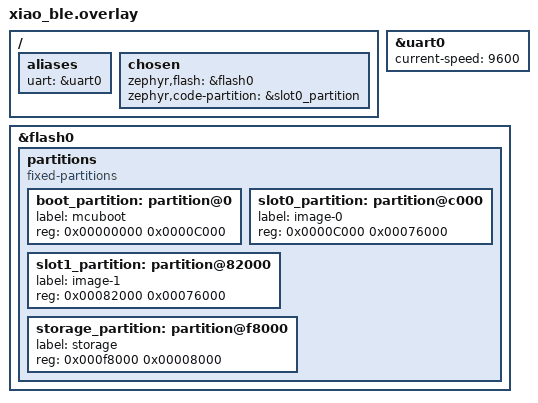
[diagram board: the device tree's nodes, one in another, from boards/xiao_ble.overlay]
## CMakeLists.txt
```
cmake_minimum_required(VERSION 3.20.0)

# Specify the C standard
set(CMAKE_C_STANDARD 17)
set(CMAKE_EXPORT_COMPILE_COMMANDS ON)

add_compile_definitions(ZB_ZCL_SUPPORT_CLUSTER_ELECTRICAL_MEASUREMENT=1)

find_package(Zephyr REQUIRED HINTS $ENV{ZEPHYR_BASE})
project("Smart Meter Zigbee")

FILE(GLOB app_sources src/*.c)
FILE(GLOB libsml_sources libsml/sml/src/*.c)
list(REMOVE_ITEM libsml_sources "${CMAKE_CURRENT_SOURCE_DIR}/libsml/sml/src/sml_transport.c")

target_compile_options(app PRIVATE -Wall -Wextra)
target_sources(app PRIVATE ${app_sources} ${libsml_sources})
target_include_directories(app PRIVATE ${CMAKE_CURRENT_SOURCE_DIR}/inc ${CMAKE_CURRENT_SOURCE_DIR}/libsml/sml/include)
target_compile_definitions(app PRIVATE SML_NO_UUID_LIB=1)
```

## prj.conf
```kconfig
# LOG configuration
CONFIG_LOG=n
CONFIG_LOG_CMDS=n

CONFIG_GPIO=n

# bootloader config
CONFIG_BUILD_OUTPUT_UF2=n
CONFIG_BOOTLOADER_MCUBOOT=y


# Shell
CONFIG_SHELL=n
# CONFIG_SHELL_BACKEND_SERIAL_RX_RING_BUFFER_SIZE=128


# Zigbee
CONFIG_ZIGBEE=y
CONFIG_ZIGBEE_APP_UTILS=y
CONFIG_ZIGBEE_ROLE_ROUTER=y
CONFIG_ZIGBEE_CHANNEL=11

CONFIG_BOOT_DELAY=0

# Enable nRF ECB driver
CONFIG_CRYPTO=y
CONFIG_CRYPTO_NRF_ECB=y
CONFIG_CRYPTO_INIT_PRIORITY=80

# This example requires more workqueue stack
CONFIG_SYSTEM_WORKQUEUE_STACK_SIZE=2048
CONFIG_MAIN_THREAD_PRIORITY=7

# LIBC config
#CONFIG_MINIMAL_LIBC_MALLOC_ARENA_SIZE=32768
CONFIG_NEWLIB_LIBC=y

# Networking
CONFIG_NET_IPV6=n
CONFIG_NET_IP_ADDR_CHECK=n
CONFIG_NET_UDP=n

#######################
# Zigbee FOTA overlay #
#######################

# Enable Zigbee FOTA library
CONFIG_ZIGBEE_FOTA=y
CONFIG_ZIGBEE_FOTA_HW_VERSION=52
CONFIG_ZIGBEE_FOTA_ENDPOINT=5
CONFIG_MCUBOOT_IMAGE_VERSION="0.1.0"
CONFIG_ZIGBEE_FOTA_COMMENT="SMZ"

# Ensure an MCUboot-compatible binary is generated.
CONFIG_IMG_MANAGER=y
CONFIG_DFU_TARGET_MCUBOOT=y
CONFIG_IMG_ERASE_PROGRESSIVELY=y
CONFIG_ZIGBEE_FOTA_PROGRESS_EVT=y

# Increase the number of RX buffers
CONFIG_NRF_802154_RX_BUFFERS=32
```

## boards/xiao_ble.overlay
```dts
/ {
     aliases {
             uart = &uart0;
     };
    chosen {
        zephyr,flash = &flash0;
        zephyr,code-partition = &slot0_partition;
    };
};

&uart0 {
    current-speed = <9600>;
};


/* Delete the existing partitions */
/delete-node/ &sd_partition;
/delete-node/ &code_partition;
/delete-node/ &storage_partition;
/delete-node/ &boot_partition;
&flash0 {
    partitions {
        compatible = "fixed-partitions";
        #address-cells = <1>;
        #size-cells = <1>;

        boot_partition: partition@0 {
            label = "mcuboot";
            reg = <0x00000000 0x0000C000>;
        };
        slot0_partition: partition@c000 {
            label = "image-0";
            reg = <0x0000C000 0x00076000>;
        };
        slot1_partition: partition@82000 {
            label = "image-1";
            reg = <0x00082000 0x00076000>;
        };
        /*
         * The flash starting at 0x000f8000 and ending at
         * 0x000fffff is reserved for use by the application.
         *
         * Storage partition will be used by FCB/LittleFS/NVS
         * if enabled.
         */
        storage_partition: partition@f8000 {
            label = "storage";
            reg = <0x000f8000 0x00008000>;
        };
    };
};
```

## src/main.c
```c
/* Includes ------------------------------------------------------------------*/
#include "sml_processing.h"
#include "zigbee.h"
/* LOG channel def -----------------------------------------------------------*/
/* Private typedef -----------------------------------------------------------*/
/* Private define ------------------------------------------------------------*/
/* Private macro -------------------------------------------------------------*/
/* Private variables ---------------------------------------------------------*/
/* Private function prototypes -----------------------------------------------*/
/* Private functions ---------------------------------------------------------*/
void main(void) {
    if (init_sml_processing() != 0) {
        return;
    }
    // The Zigbee thread will wait until the first sml message
    start_zigbee();
    start_sml_processing();
}
/* Exported functions --------------------------------------------------------*/
```

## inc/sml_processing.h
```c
/* Define to prevent recursive inclusion -------------------------------------*/
#ifndef SML_PROCESSING_H
#define SML_PROCESSING_H
/* Includes ------------------------------------------------------------------*/
/* Exported types ------------------------------------------------------------*/
/* Exported constants --------------------------------------------------------*/
/* Exported macro ------------------------------------------------------------*/
/* Exported variables --------------------------------------------------------*/
/* Exported functions --------------------------------------------------------*/
/* Initialization and Configuration functions  ******************************/
int init_sml_processing(void);
void start_sml_processing(void);
/* Private types -------------------------------------------------------------*/
/* Private variables ---------------------------------------------------------*/
/* Private constants ---------------------------------------------------------*/
#define SML_RX_BUFFER_SIZE 1024
/* Private macros ------------------------------------------------------------*/
/* Private functions ---------------------------------------------------------*/

#endif  // SML_PROCESSING_H
```

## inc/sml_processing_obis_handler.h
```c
/* Define to prevent recursive inclusion -------------------------------------*/
#ifndef SML_PROCESSING_OBIS_HANDLER_H
#define SML_PROCESSING_OBIS_HANDLER_H
/* Includes ------------------------------------------------------------------*/
#include <zephyr/sys/atomic.h>

#include "sml/sml_list.h"
/* Exported types ------------------------------------------------------------*/
/* Exported constants --------------------------------------------------------*/
typedef enum {
    ACTIVE_ENERGY_IMPORT_FLAG = 1 << 0,
    ACTIVE_ENERGY_EXPORT_FLAG = 1 << 1,
    CURRENT_ACTIVE_POWER_FLAG = 1 << 2,
    VOLTAGE_L1_FLAG = 1 << 3,
    VOLTAGE_L2_FLAG = 1 << 4,
    VOLTAGE_L3_FLAG = 1 << 5,
    CURRENT_L1_FLAG = 1 << 6,
    CURRENT_L2_FLAG = 1 << 7,
    CURRENT_L3_FLAG = 1 << 8,
    ANGLE_L1_FLAG = 1 << 9,
    ANGLE_L2_FLAG = 1 << 10,
    ANGLE_L3_FLAG = 1 << 11,
    FREQUENCY_FLAG = 1 << 12,
} sml_obis_flag_t;
/* Exported macro ------------------------------------------------------------*/
/* Exported variables --------------------------------------------------------*/
extern atomic_t sml_obis_initialized;
/* Exported functions --------------------------------------------------------*/
void process_active_energy_import(sml_list *entry);
void process_current_active_power(sml_list *entry);
void process_voltage_l1(sml_list *entry);
void process_voltage_l2(sml_list *entry);
void process_voltage_l3(sml_list *entry);
void process_current_l1(sml_list *entry);
void process_current_l2(sml_list *entry);
void process_current_l3(sml_list *entry);
void process_frequency(sml_list *entry);
void process_default_handler(sml_list *entry);
void ignore_obis_value(sml_list *entry);
/* Private types -------------------------------------------------------------*/
/* Private variables ---------------------------------------------------------*/

/* Private constants ---------------------------------------------------------*/
/* Private macros ------------------------------------------------------------*/
/* Private functions ---------------------------------------------------------*/




#endif  // SML_PROCESSING_OBIS_HANDLER_H
```

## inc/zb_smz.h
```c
/* Define to prevent recursive inclusion -------------------------------------*/
#ifndef ZB_SMZ_H
#define ZB_SMZ_H
/* Includes ------------------------------------------------------------------*/
#include <zboss_api.h>
/* Exported types ------------------------------------------------------------*/
typedef struct {
    zb_uint32_t measurement_type;
    zb_uint16_t rmsCurrentPhA;
    zb_uint16_t rmsCurrentPhB;
    zb_uint16_t rmsCurrentPhC;
    zb_uint16_t rmsVoltagePhA;
    zb_uint16_t rmsVoltagePhB;
    zb_uint16_t rmsVoltagePhC;
    zb_uint16_t acFrequency;
    zb_uint16_t voltageMultiplier;
    zb_uint16_t voltageDivisor;
    zb_uint16_t currentMultiplier;
    zb_uint16_t currentDivisor;
    zb_uint16_t powerMultiplier;
    zb_uint16_t powerDivisor;
    zb_uint16_t frequencyMultiplier;
    zb_uint16_t frequencyDivisor;
    zb_uint16_t powerFactor;
} zb_zcl_el_measurement_attrs_ext_t;

typedef struct {
    zb_uint48_t curr_summ_delivered;
    zb_int24_t instantaneous_demand;
    zb_uint24_t multiplier;
    zb_uint24_t divisor;
} zb_zcl_metering_attrs_custom_t;
/* Exported constants --------------------------------------------------------*/
/** SMZ Device ID*/
#define ZB_SMZ_DEVICE_ID 0x0008
/** SMZ device version */
#define ZB_DEVICE_VER_SMZ 0
/** SMZ IN (server) clusters number */
#define ZB_SMZ_IN_CLUSTER_NUM 4
/** SMZ OUT (client) clusters number */
#define ZB_SMZ_OUT_CLUSTER_NUM 0
#define ZB_SMZ_CLUSTER_NUM (ZB_SMZ_IN_CLUSTER_NUM + ZB_SMZ_OUT_CLUSTER_NUM)
#define ZB_SMZ_EL_REPORT_COUNT 7
#define ZB_SMZ_METERING_REPORT_COUNT 2
/** Number of attribute for reporting on SMZ device */
#define ZB_SMZ_REPORT_ATTR_COUNT ZB_SMZ_EL_REPORT_COUNT + ZB_SMZ_METERING_REPORT_COUNT
/* Exported macro ------------------------------------------------------------*/
#define ZB_SET_ATTR_DESCR_WITH_ZB_ZCL_ATTR_ELECTRICAL_MEASUREMENT_ACTIVE_POWER_PHB_ID(data_ptr) \
    {                                                                                           \
        ZB_ZCL_ATTR_ELECTRICAL_MEASUREMENT_ACTIVE_POWER_PHB_ID, ZB_ZCL_ATTR_TYPE_S16,           \
            ZB_ZCL_ATTR_ACCESS_READ_ONLY | ZB_ZCL_ATTR_ACCESS_REPORTING, (void *)data_ptr       \
    }

#define ZB_SET_ATTR_DESCR_WITH_ZB_ZCL_ATTR_ELECTRICAL_MEASUREMENT_ACTIVE_POWER_PHC_ID(data_ptr) \
    {                                                                                           \
        ZB_ZCL_ATTR_ELECTRICAL_MEASUREMENT_ACTIVE_POWER_PHC_ID, ZB_ZCL_ATTR_TYPE_S16,           \
            ZB_ZCL_ATTR_ACCESS_READ_ONLY | ZB_ZCL_ATTR_ACCESS_REPORTING, (void *)data_ptr       \
    }

#define ZB_SET_ATTR_DESCR_WITH_ZB_ZCL_ATTR_ELECTRICAL_MEASUREMENT_RMSCURRENT_PHB_ID(data_ptr) \
    {                                                                                         \
        ZB_ZCL_ATTR_ELECTRICAL_MEASUREMENT_RMSCURRENT_PHB_ID, ZB_ZCL_ATTR_TYPE_U16,           \
            ZB_ZCL_ATTR_ACCESS_READ_ONLY | ZB_ZCL_ATTR_ACCESS_REPORTING, (void *)data_ptr     \
    }

#define ZB_SET_ATTR_DESCR_WITH_ZB_ZCL_ATTR_ELECTRICAL_MEASUREMENT_RMSCURRENT_PHC_ID(data_ptr) \
    {                                                                                         \
        ZB_ZCL_ATTR_ELECTRICAL_MEASUREMENT_RMSCURRENT_PHC_ID, ZB_ZCL_ATTR_TYPE_U16,           \
            ZB_ZCL_ATTR_ACCESS_READ_ONLY | ZB_ZCL_ATTR_ACCESS_REPORTING, (void *)data_ptr     \
    }

#define ZB_SET_ATTR_DESCR_WITH_ZB_ZCL_ATTR_ELECTRICAL_MEASUREMENT_RMSVOLTAGE_PHB_ID(data_ptr) \
    {                                                                                         \
        ZB_ZCL_ATTR_ELECTRICAL_MEASUREMENT_RMSVOLTAGE_PHB_ID, ZB_ZCL_ATTR_TYPE_U16,           \
            ZB_ZCL_ATTR_ACCESS_READ_ONLY | ZB_ZCL_ATTR_ACCESS_REPORTING, (void *)data_ptr     \
    }

#define ZB_SET_ATTR_DESCR_WITH_ZB_ZCL_ATTR_ELECTRICAL_MEASUREMENT_RMSVOLTAGE_PHC_ID(data_ptr) \
    {                                                                                         \
        ZB_ZCL_ATTR_ELECTRICAL_MEASUREMENT_RMSVOLTAGE_PHC_ID, ZB_ZCL_ATTR_TYPE_U16,           \
            ZB_ZCL_ATTR_ACCESS_READ_ONLY | ZB_ZCL_ATTR_ACCESS_REPORTING, (void *)data_ptr     \
    }

#define ZB_SET_ATTR_DESCR_WITH_ZB_ZCL_ATTR_ELECTRICAL_MEASUREMENT_AC_FREQUENCY_ID(data_ptr) \
    {                                                                                       \
        ZB_ZCL_ATTR_ELECTRICAL_MEASUREMENT_AC_FREQUENCY_ID, ZB_ZCL_ATTR_TYPE_U16,           \
            ZB_ZCL_ATTR_ACCESS_READ_ONLY | ZB_ZCL_ATTR_ACCESS_REPORTING, (void *)data_ptr   \
    }

#define ZB_SET_ATTR_DESCR_WITH_ZB_ZCL_ATTR_METERING_CURRENT_SUMMATION_RECEIVED_ID(data_ptr) \
    {                                                                                       \
        ZB_ZCL_ATTR_METERING_CURRENT_SUMMATION_RECEIVED_ID, ZB_ZCL_ATTR_TYPE_U48,           \
            ZB_ZCL_ATTR_ACCESS_READ_ONLY | ZB_ZCL_ATTR_ACCESS_REPORTING, (void *)data_ptr   \
    }

#define ZB_SET_ATTR_DESCR_WITH_ZB_ZCL_ATTR_ELECTRICAL_MEASUREMENT_AC_FREQUENCY_MULTIPLIER_ID(data_ptr) \
    {                                                                                                  \
        ZB_ZCL_ATTR_ELECTRICAL_MEASUREMENT_AC_FREQUENCY_MULTIPLIER_ID, ZB_ZCL_ATTR_TYPE_U16,           \
            ZB_ZCL_ATTR_ACCESS_READ_ONLY, (void *)data_ptr                                             \
    }

#define ZB_SET_ATTR_DESCR_WITH_ZB_ZCL_ATTR_ELECTRICAL_MEASUREMENT_AC_FREQUENCY_DIVISOR_ID(data_ptr) \
    {                                                                                               \
        ZB_ZCL_ATTR_ELECTRICAL_MEASUREMENT_AC_FREQUENCY_DIVISOR_ID, ZB_ZCL_ATTR_TYPE_U16,           \
            ZB_ZCL_ATTR_ACCESS_READ_ONLY, (void *)data_ptr                                          \
    }

#define ZB_SET_ATTR_DESCR_WITH_ZB_ZCL_ATTR_ELECTRICAL_MEASUREMENT_ACCURRENT_MULTIPLIER_ID(data_ptr) \
    {                                                                                               \
        ZB_ZCL_ATTR_ELECTRICAL_MEASUREMENT_ACCURRENT_MULTIPLIER_ID, ZB_ZCL_ATTR_TYPE_U16,           \
            ZB_ZCL_ATTR_ACCESS_READ_ONLY, (void *)data_ptr                                          \
    }

#define ZB_SET_ATTR_DESCR_WITH_ZB_ZCL_ATTR_ELECTRICAL_MEASUREMENT_ACCURRENT_DIVISOR_ID(data_ptr)                     \
    {                                                                                                                \
        ZB_ZCL_ATTR_ELECTRICAL_MEASUREMENT_ACCURRENT_DIVISOR_ID, ZB_ZCL_ATTR_TYPE_U16, ZB_ZCL_ATTR_ACCESS_READ_ONLY, \
            (void *)data_ptr                                                                                         \
    }

#define ZB_SET_ATTR_DESCR_WITH_ZB_ZCL_ATTR_ELECTRICAL_MEASUREMENT_ACVOLTAGE_MULTIPLIER_ID(data_ptr) \
    {                                                                                               \
        ZB_ZCL_ATTR_ELECTRICAL_MEASUREMENT_ACVOLTAGE_MULTIPLIER_ID, ZB_ZCL_ATTR_TYPE_U16,           \
            ZB_ZCL_ATTR_ACCESS_READ_ONLY, (void *)data_ptr                                          \
    }

#define ZB_SET_ATTR_DESCR_WITH_ZB_ZCL_ATTR_ELECTRICAL_MEASUREMENT_ACVOLTAGE_DIVISOR_ID(data_ptr)                     \
    {                                                                                                                \
        ZB_ZCL_ATTR_ELECTRICAL_MEASUREMENT_ACVOLTAGE_DIVISOR_ID, ZB_ZCL_ATTR_TYPE_U16, ZB_ZCL_ATTR_ACCESS_READ_ONLY, \
            (void *)data_ptr                                                                                         \
    }

/** @brief Declare attribute list for Electrical Measurement cluster
        @param attr_list - attribute list name
        @param measurement_type - pointer to variable to store Measurement Type
     attribute value
        @param s - zb_zcl_el_measurement_attrs_ext_t struct
*/
#define ZB_ZCL_DECLARE_ELECTRICAL_MEASUREMENT_ATTRIB_LIST_EXT(                                                         \
    attr_list, measurement_type, rmsCurrentPhA, rmsCurrentPhB, rmsCurrentPhC, rmsVoltagePhA, rmsVoltagePhB,            \
    rmsVoltagePhC, acFrequency, voltageMultiplier, voltageDivisor, currentMultiplier, currentDivisor, powerMultiplier, \
    powerDivisor, frequencyMultiplier, frequencyDivisor, powerFactor)                                                  \
    ZB_ZCL_START_DECLARE_ATTRIB_LIST_CLUSTER_REVISION(attr_list, ZB_ZCL_ELECTRICAL_MEASUREMENT)                        \
    ZB_ZCL_SET_ATTR_DESC(ZB_ZCL_ATTR_ELECTRICAL_MEASUREMENT_MEASUREMENT_TYPE_ID, (measurement_type))                   \
    ZB_ZCL_SET_ATTR_DESC(ZB_ZCL_ATTR_ELECTRICAL_MEASUREMENT_RMSCURRENT_ID, (rmsCurrentPhA))                            \
    ZB_ZCL_SET_ATTR_DESC(ZB_ZCL_ATTR_ELECTRICAL_MEASUREMENT_RMSCURRENT_PHB_ID, (rmsCurrentPhB))                        \
    ZB_ZCL_SET_ATTR_DESC(ZB_ZCL_ATTR_ELECTRICAL_MEASUREMENT_RMSCURRENT_PHC_ID, (rmsCurrentPhC))                        \
    ZB_ZCL_SET_ATTR_DESC(ZB_ZCL_ATTR_ELECTRICAL_MEASUREMENT_RMSVOLTAGE_ID, (rmsVoltagePhA))                            \
    ZB_ZCL_SET_ATTR_DESC(ZB_ZCL_ATTR_ELECTRICAL_MEASUREMENT_RMSVOLTAGE_PHB_ID, (rmsVoltagePhB))                        \
    ZB_ZCL_SET_ATTR_DESC(ZB_ZCL_ATTR_ELECTRICAL_MEASUREMENT_RMSVOLTAGE_PHC_ID, (rmsVoltagePhC))                        \
    ZB_ZCL_SET_ATTR_DESC(ZB_ZCL_ATTR_ELECTRICAL_MEASUREMENT_AC_FREQUENCY_ID, (acFrequency))                            \
    ZB_ZCL_SET_ATTR_DESC(ZB_ZCL_ATTR_ELECTRICAL_MEASUREMENT_ACVOLTAGE_MULTIPLIER_ID, (voltageMultiplier))              \
    ZB_ZCL_SET_ATTR_DESC(ZB_ZCL_ATTR_ELECTRICAL_MEASUREMENT_ACVOLTAGE_DIVISOR_ID, (voltageDivisor))                    \
    ZB_ZCL_SET_ATTR_DESC(ZB_ZCL_ATTR_ELECTRICAL_MEASUREMENT_ACCURRENT_MULTIPLIER_ID, (currentMultiplier))              \
    ZB_ZCL_SET_ATTR_DESC(ZB_ZCL_ATTR_ELECTRICAL_MEASUREMENT_ACCURRENT_DIVISOR_ID, (currentDivisor))                    \
    ZB_ZCL_SET_ATTR_DESC(ZB_ZCL_ATTR_ELECTRICAL_MEASUREMENT_ACPOWER_MULTIPLIER_ID, (powerMultiplier))                  \
    ZB_ZCL_SET_ATTR_DESC(ZB_ZCL_ATTR_ELECTRICAL_MEASUREMENT_ACPOWER_DIVISOR_ID, (powerDivisor))                        \
    ZB_ZCL_SET_ATTR_DESC(ZB_ZCL_ATTR_ELECTRICAL_MEASUREMENT_AC_FREQUENCY_MULTIPLIER_ID, (frequencyMultiplier))         \
    ZB_ZCL_SET_ATTR_DESC(ZB_ZCL_ATTR_ELECTRICAL_MEASUREMENT_AC_FREQUENCY_DIVISOR_ID, (frequencyDivisor))               \
    ZB_ZCL_SET_ATTR_DESC(ZB_ZCL_ATTR_ELECTRICAL_MEASUREMENT_POWER_FACTOR_ID, (powerFactor))                            \
    ZB_ZCL_FINISH_DECLARE_ATTRIB_LIST

#define ZB_ZCL_DECLARE_METERING_ATTRIB_LIST_CUSTOM(attr_list, curr_summ_delivered, instantaneous_demand, multiplier, \
                                                   divisor)                                                          \
    ZB_ZCL_START_DECLARE_ATTRIB_LIST_CLUSTER_REVISION(attr_list, ZB_ZCL_METERING)                                    \
    ZB_ZCL_SET_ATTR_DESC(ZB_ZCL_ATTR_METERING_CURRENT_SUMMATION_DELIVERED_ID, (curr_summ_delivered))                 \
    ZB_ZCL_SET_ATTR_DESC(ZB_ZCL_ATTR_METERING_INSTANTANEOUS_DEMAND_ID, (instantaneous_demand))                       \
    ZB_ZCL_SET_ATTR_DESC(ZB_ZCL_ATTR_METERING_MULTIPLIER_ID, (multiplier))                                           \
    ZB_ZCL_SET_ATTR_DESC(ZB_ZCL_ATTR_METERING_DIVISOR_ID, (divisor))                                                 \
    ZB_ZCL_FINISH_DECLARE_ATTRIB_LIST

/**
 * @brief Declare cluster list for SMZ device
 * @param cluster_list_name - cluster list variable name
 * @param basic_attr_list - attribute list for Basic cluster
 * @param identify_attr_list - attribute list for Identify cluster
 * @param el_measurment_attr_list - attribute list for electrical measurment
 * @param metering_attr_list - attribute list for metering
 * cluster
 */
#define ZB_DECLARE_SMZ_CLUSTER_LIST(cluster_list_name, basic_attr_list, identify_attr_list, el_measurment_attr_list, \
                                    metering_attr_list)                                                              \
    zb_zcl_cluster_desc_t cluster_list_name[] = {                                                                    \
        ZB_ZCL_CLUSTER_DESC(ZB_ZCL_CLUSTER_ID_METERING, ZB_ZCL_ARRAY_SIZE(metering_attr_list, zb_zcl_attr_t),        \
                            (metering_attr_list), ZB_ZCL_CLUSTER_SERVER_ROLE, ZB_ZCL_MANUF_CODE_INVALID),            \
        ZB_ZCL_CLUSTER_DESC(ZB_ZCL_CLUSTER_ID_ELECTRICAL_MEASUREMENT,                                                \
                            ZB_ZCL_ARRAY_SIZE(el_measurment_attr_list, zb_zcl_attr_t), (el_measurment_attr_list),    \
                            ZB_ZCL_CLUSTER_SERVER_ROLE, ZB_ZCL_MANUF_CODE_INVALID),                                  \
        ZB_ZCL_CLUSTER_DESC(ZB_ZCL_CLUSTER_ID_IDENTIFY, ZB_ZCL_ARRAY_SIZE(identify_attr_list, zb_zcl_attr_t),        \
                            (identify_attr_list), ZB_ZCL_CLUSTER_SERVER_ROLE, ZB_ZCL_MANUF_CODE_INVALID),            \
        ZB_ZCL_CLUSTER_DESC(ZB_ZCL_CLUSTER_ID_BASIC, ZB_ZCL_ARRAY_SIZE(basic_attr_list, zb_zcl_attr_t),              \
                            (basic_attr_list), ZB_ZCL_CLUSTER_SERVER_ROLE, ZB_ZCL_MANUF_CODE_INVALID)}

/** @cond internals_doc */

/**
 * @brief Declare simple descriptor for SMZ device
 * @param ep_name - endpoint variable name
 * @param ep_id - endpoint ID
 * @param in_clust_num - number of supported input clusters
 * @param out_clust_num - number of supported output clusters
 */
#define ZB_ZCL_DECLARE_SMZ_SIMPLE_DESC(ep_name, ep_id, in_clust_num, out_clust_num) \
    ZB_DECLARE_SIMPLE_DESC(in_clust_num, out_clust_num);                            \
    ZB_AF_SIMPLE_DESC_TYPE(in_clust_num, out_clust_num)                             \
    simple_desc_##ep_name = {ep_id,                                                 \
                             ZB_AF_HA_PROFILE_ID,                                   \
                             ZB_SMZ_DEVICE_ID,                                      \
                             ZB_DEVICE_VER_SMZ,                                     \
                             0,                                                     \
                             in_clust_num,                                          \
                             out_clust_num,                                         \
                             {                                                      \
                                 ZB_ZCL_CLUSTER_ID_BASIC,                           \
                                 ZB_ZCL_CLUSTER_ID_IDENTIFY,                        \
                                 ZB_ZCL_CLUSTER_ID_ELECTRICAL_MEASUREMENT,          \
                                 ZB_ZCL_CLUSTER_ID_METERING,                        \
                             }}
/**
 * @brief Declare endpoint for SMZ device
 * @param ep_name - endpoint variable name
 * @param ep_id - endpoint ID
 * @param cluster_list - endpoint cluster list
 */
#define ZB_DECLARE_SMZ_EP(ep_name, ep_id, cluster_list)                                                      \
    ZB_ZCL_DECLARE_SMZ_SIMPLE_DESC(ep_name, ep_id, ZB_SMZ_IN_CLUSTER_NUM, ZB_SMZ_OUT_CLUSTER_NUM);           \
    ZBOSS_DEVICE_DECLARE_REPORTING_CTX(reporting_info##ep_name, ZB_SMZ_REPORT_ATTR_COUNT);                   \
    ZB_AF_DECLARE_ENDPOINT_DESC(ep_name, ep_id, ZB_AF_HA_PROFILE_ID, 0, NULL,                                \
                                ZB_ZCL_ARRAY_SIZE(cluster_list, zb_zcl_cluster_desc_t), cluster_list,        \
                                (zb_af_simple_desc_1_1_t *)&simple_desc_##ep_name, ZB_SMZ_REPORT_ATTR_COUNT, \
                                reporting_info##ep_name, 0, NULL) /* No CVC ctx */
/* Exported variables --------------------------------------------------------*/
/* Exported functions --------------------------------------------------------*/
/* Initialization and Configuration functions  ******************************/
/* Private types -------------------------------------------------------------*/
/* Private variables ---------------------------------------------------------*/

/* Private constants ---------------------------------------------------------*/
/* Private macros ------------------------------------------------------------*/
/* Private functions ---------------------------------------------------------*/

#endif /* ZB_SMZ_H */
```

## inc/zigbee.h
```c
/* Define to prevent recursive inclusion -------------------------------------*/
#ifndef ZB_DEVICE_CLUSTERS_H_
#define ZB_DEVICE_CLUSTERS_H_
/* Includes ------------------------------------------------------------------*/
#include <zboss_api.h>
/* Exported types ------------------------------------------------------------*/
/* Exported constants --------------------------------------------------------*/
/* Device endpoint, used to receive ZCL commands. */
#define SMZ_ENDPOINT_ID 10
#define SML_INIT_BASIC_POWER_SOURCE ZB_ZCL_BASIC_POWER_SOURCE_DC_SOURCE
/* Version of the application software (1 byte). */
#define SMZ_INIT_BASIC_APP_VERSION 01
/* Version of the implementation of the Zigbee stack (1 byte). */
#define SMZ_INIT_BASIC_STACK_VERSION 10
/* Version of the hardware of the device (1 byte). */
#define SMZ_INIT_BASIC_HW_VERSION 11
/* Manufacturer name (32 bytes). */
#define SMZ_INIT_BASIC_MANUF_NAME "Knoedelauflauf"
/* Model number assigned by manufacturer (32-bytes long string). */
#define SMZ_INIT_BASIC_MODEL_ID "SMZ_v0.1"
/* First 8 bytes specify the date of manufacturer of the device
 * in ISO 8601 format (YYYYMMDD). The rest (8 bytes) are manufacturer specific.
 */
#define SMZ_INIT_BASIC_DATE_CODE "20230404"
/* Describes the type of physical environment.
 * For possible values see section 3.2.2.2.10 of ZCL specification.
 */
#define SMZ_INIT_BASIC_PH_ENV ZB_ZCL_BASIC_ENV_UNSPECIFIED
/* Exported macro ------------------------------------------------------------*/
/* Exported variables --------------------------------------------------------*/
/* Exported functions --------------------------------------------------------*/
/* Initialization and Configuration functions  ******************************/
void start_zigbee();
/* Private types -------------------------------------------------------------*/
/* Private variables ---------------------------------------------------------*/

/* Private constants ---------------------------------------------------------*/
#define REQUIRED_OBIS (ACTIVE_ENERGY_IMPORT_FLAG | CURRENT_ACTIVE_POWER_FLAG)
/* Private macros ------------------------------------------------------------*/
/* Private functions ---------------------------------------------------------*/

#endif // ZB_DEVICE_CLUSTERS_H_
```

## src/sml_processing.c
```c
/* Includes ------------------------------------------------------------------*/
#include "sml_processing.h"

#include <errno.h>
#include <math.h>
#include <sml/sml_crc16.h>
#include <sml/sml_file.h>
#include <stdio.h>
#include <string.h>
#include <zboss_api.h>
#include <zcl/zb_zcl_el_measurement.h>
#include <zcl/zb_zcl_metering.h>
#include <zephyr/device.h>
#include <zephyr/drivers/uart.h>
#include <zephyr/kernel.h>
#include <zephyr/logging/log.h>
#include <zephyr/sys/atomic_builtin.h>
#include <zephyr/sys/byteorder.h>
#include <zephyr/sys/util.h>

#include "sml_processing_obis_handler.h"
#include "zb_config_platform.h"
#include "zephyr/toolchain/gcc.h"
/* LOG channel def -----------------------------------------------------------*/
LOG_MODULE_REGISTER(sml_processing, LOG_LEVEL_WRN);
/* Thread Storage def --------------------------------------------------------*/
K_THREAD_STACK_DEFINE(sml_parsing_thread_stack, 2048);
/* Private typedef -----------------------------------------------------------*/
typedef struct {
    const uint8_t OBIS[6];
    const char *description;
    void (*process_value)(sml_list *entry);
} obis_mapping_t;
/* Private define ------------------------------------------------------------*/
/* change this to any other UART peripheral if desired */
#define UART_DEVICE_NODE DT_ALIAS(uart)
#define SML_START_SEQUENCE_LENGTH 8
#define SML_START_SEQUENCE "\x1B\x1B\x1B\x1B\x01\x01\x01\x01"
/* Private macro -------------------------------------------------------------*/
/* Private constants ---------------------------------------------------------*/
static const struct device *const uart_dev = DEVICE_DT_GET(UART_DEVICE_NODE);
/* Private variables ---------------------------------------------------------*/
static uint8_t sml_msg_buffer[SML_RX_BUFFER_SIZE];
static size_t sml_msg_buffer_pos;
static atomic_t processing_thread_running = 0;
static struct k_sem sml_msg_received_sem;
static struct k_thread sml_parsing_thread_data;
static const obis_mapping_t obis_mappings[] = {
    {{0x01, 0x00, 0x01, 0x08, 0x00, 0xff}, "Active Energy Import", process_active_energy_import},
    {{0x01, 0x00, 0x10, 0x07, 0x00, 0xff}, "Current Active Power", process_current_active_power},
    {{0x01, 0x00, 0x20, 0x07, 0x00, 0xff}, "Voltage L1", process_voltage_l1},
    {{0x01, 0x00, 0x34, 0x07, 0x00, 0xff}, "Voltage L2", process_voltage_l2},
    {{0x01, 0x00, 0x48, 0x07, 0x00, 0xff}, "Voltage L3", process_voltage_l3},
    {{0x01, 0x00, 0x1F, 0x07, 0x00, 0xff}, "Current L1", process_current_l1},
    {{0x01, 0x00, 0x33, 0x07, 0x00, 0xff}, "Current L2", process_current_l2},
    {{0x01, 0x00, 0x47, 0x07, 0x00, 0xff}, "Current L3", process_current_l3},
    {{0x01, 0x00, 0x0E, 0x07, 0x00, 0xff}, "Frequency", process_frequency},

    {{0x01, 0x00, 0x02, 0x08, 0x00, 0xff}, "Active Energy Export", ignore_obis_value},
    {{0x01, 0x00, 0x51, 0x07, 0x04, 0xff}, "Angle L1", ignore_obis_value},
    {{0x01, 0x00, 0x51, 0x07, 0x0F, 0xff}, "Angle L2", ignore_obis_value},
    {{0x01, 0x00, 0x51, 0x07, 0x1A, 0xff}, "Angle L3", ignore_obis_value},
    {{0x01, 0x00, 0x00, 0x02, 0x00, 0x00}, "LR-Firmware Version", ignore_obis_value},
    {{0x01, 0x00, 0x00, 0x02, 0x00, 0x01}, "NLR-Firmware Version", ignore_obis_value},
    {{0x01, 0x00, 0x60, 0x5A, 0x02, 0x01}, "LR-Firmware CRC", ignore_obis_value},
    {{0x01, 0x00, 0x60, 0x5A, 0x02, 0x02}, "NLR-Firmware CRC", ignore_obis_value},
    {{0x01, 0x00, 0x60, 0x32, 0x01, 0x01}, "Power Threshold", ignore_obis_value},
    {{0x01, 0x00, 0x60, 0x01, 0x00, 0xff}, "Equipment Identifier", ignore_obis_value},
    // Add more OBIS mappings here as needed
};
/* Private function prototypes -----------------------------------------------*/
/* Private functions ---------------------------------------------------------*/
// Function to process SML files and print active energy OBIS numbers
void parse_sml_data(uint8_t *buffer, size_t buffer_size) {
    sml_file *file = sml_file_parse(buffer, buffer_size);
    if (!file) {
        LOG_ERR("Error parsing SML data.\n");
        return;
    }
    // sml_file_print(file);

    for (int i = 0; i < file->messages_len; i++) {
        sml_message *message = file->messages[i];
        if (*message->message_body->tag != SML_MESSAGE_GET_LIST_RESPONSE) {
            continue;
        }

        sml_get_list_response *resp = (sml_get_list_response *)message->message_body->data;
        for (sml_list *entry = resp->val_list; entry != NULL; entry = entry->next) {
            if (!entry->value) {
                LOG_ERR("Error in data stream. entry->value should not be NULL. Skipping this.\n");
                continue;
            }
            // Process the OBIS code in the value entry
            bool obis_handler_found = false;
            for (size_t i = 0; i < ARRAY_SIZE(obis_mappings); i++) {
                if (entry->obj_name->len != 6) {
                    LOG_ERR("Not len 6\n");
                    continue;
                }
                if (memcmp(entry->obj_name->str, obis_mappings[i].OBIS, 6) == 0) {
                    LOG_INF("%s: ", obis_mappings[i].description);
                    obis_mappings[i].process_value(entry);
                    obis_handler_found = true;
                    break;
                }
            }
            // Call the default handler if no matching OBIS handler is found
            if (!obis_handler_found) {
                process_default_handler(entry);
            }
        }
    }

    sml_file_free(file);
}

void uart_callback(const struct device *dev, void *user_data) {
    ARG_UNUSED(dev);
    ARG_UNUSED(user_data);
    static bool message_started = false;
    if (!uart_irq_update(uart_dev)) {
        return;
    }

    if (!uart_irq_rx_ready(uart_dev)) {
        return;
    }
    uint8_t byte;
    /* read until FIFO empty */
    while (uart_fifo_read(uart_dev, &byte, 1) == 1) {
        if (atomic_get(&processing_thread_running) == false) {
            sml_msg_buffer[sml_msg_buffer_pos++] = byte;

            // Search for the start of an SML message
            if (!message_started) {
                if (sml_msg_buffer_pos >= SML_START_SEQUENCE_LENGTH) {
                    if (memcmp(sml_msg_buffer + sml_msg_buffer_pos - SML_START_SEQUENCE_LENGTH, SML_START_SEQUENCE,
                               SML_START_SEQUENCE_LENGTH) == 0) {
                        message_started = true;
                        LOG_DBG("Message started.");
                    } else {
                        // Shift the buffer to search for the SML_START_SEQUENCE
                        memmove(sml_msg_buffer, sml_msg_buffer + 1, SML_START_SEQUENCE_LENGTH - 1);
                        sml_msg_buffer_pos--;
                    }
                }
            } else {
                // Check for the end of the SML message (Escape-Sequence and End of SML file)
                if (sml_msg_buffer_pos >= 8 &&
                    memcmp(sml_msg_buffer + sml_msg_buffer_pos - 8, "\x1b\x1b\x1b\x1b\x1a", 5) == 0) {
                    uint8_t padding = sml_msg_buffer[sml_msg_buffer_pos - 3];
                    if (sml_msg_buffer_pos >= (8 + padding)) {
                        LOG_DBG("Found end and Escape-Sequence.");
                        if (sml_crc16_calculate(sml_msg_buffer, sml_msg_buffer_pos - 2) ==
                            sys_get_be16(&sml_msg_buffer[sml_msg_buffer_pos - 2])) {
                            // Signal that a complete SML message has been received
                            LOG_DBG("Giving Semaphore. Padding: %u", padding);
                            atomic_set(&processing_thread_running, true);
                            k_sem_give(&sml_msg_received_sem);
                        } else {
                            LOG_DBG("CRC mismatch.");
                            sml_msg_buffer_pos = 0;
                        }
                        message_started = false;
                    }
                }
            }

            // If the buffer is full, reset the buffer position to prevent overflow
            if (sml_msg_buffer_pos >= SML_RX_BUFFER_SIZE) {
                LOG_ERR("SML msg buffer full.");
                sml_msg_buffer_pos = 0;
                message_started = false;
            }
        }
    }
}

void sml_parsing_thread(void *arg1, void *arg2, void *arg3) {
    ARG_UNUSED(arg1);
    ARG_UNUSED(arg2);
    ARG_UNUSED(arg3);
    while (1) {
        LOG_DBG("Waiting for Semaphore.");
        k_sem_take(&sml_msg_received_sem, K_FOREVER);
        LOG_DBG("Parsing Thread started.");
        // Parse the SML message and process the result
        parse_sml_data(sml_msg_buffer + 8, sml_msg_buffer_pos - 16);
        // Reset buffer position for the next SML message
        sml_msg_buffer_pos = 0;
        atomic_set(&processing_thread_running, false);
        LOG_DBG("Parsing Thread ended.");
    }
}
/* Exported functions --------------------------------------------------------*/
int init_sml_processing() {
    if (!device_is_ready(uart_dev)) {
        LOG_ERR("UART device not found!");
        return ENODEV;
    }

    k_sem_init(&sml_msg_received_sem, 0, 1);

    /* configure interrupt and callback to receive data */
    uart_irq_callback_user_data_set(uart_dev, uart_callback, NULL);
    uart_irq_rx_enable(uart_dev);

    return 0;
}

void start_sml_processing() {
    k_thread_create(&sml_parsing_thread_data, sml_parsing_thread_stack, K_THREAD_STACK_SIZEOF(sml_parsing_thread_stack),
                    sml_parsing_thread, NULL, NULL, NULL, K_PRIO_COOP(7), 0, K_NO_WAIT);
    k_thread_name_set(&sml_parsing_thread_data, "SML Parser");
}
```

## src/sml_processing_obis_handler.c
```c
/* Includes ------------------------------------------------------------------*/
#include "sml_processing_obis_handler.h"

#include <math.h>
#include <stdbool.h>
#include <stdint.h>
#include <string.h>
#include <zephyr/logging/log.h>

#include "zigbee.h"
/* LOG channel def -----------------------------------------------------------*/
LOG_MODULE_REGISTER(sml_obis_handler);
/* Private typedef -----------------------------------------------------------*/
/* Private define ------------------------------------------------------------*/
/* Private macro -------------------------------------------------------------*/
/* Private constants ---------------------------------------------------------*/
#define MAX_ZB_INT_BYTES 6
typedef enum {
    ZB_UINT48,
    ZB_INT24,
    ZB_UINT16,
    ZB_INT16,
} zb_type_t;
// Precomputed powers of 10 and their inverses up to 10^9 (for int32_t range)
// If you need larger exponents, add more elements to the arrays.
static const double powers_of_10[] = {1e0, 1e1, 1e2, 1e3, 1e4, 1e5, 1e6, 1e7, 1e8, 1e9};
static const double inv_powers_of_10[] = {1e0, 1e-1, 1e-2, 1e-3, 1e-4, 1e-5, 1e-6, 1e-7, 1e-8, 1e-9};
/* Private variables ---------------------------------------------------------*/
/* Private function prototypes -----------------------------------------------*/
/* Private functions ---------------------------------------------------------*/
static double pow10(int8_t exp) {
    bool is_negative = exp < 0;
    uint8_t exp_abs = (is_negative) ? (uint8_t)-exp : (uint8_t)exp;

    if (exp_abs < sizeof(powers_of_10) / sizeof(powers_of_10[0])) {
        return (is_negative) ? inv_powers_of_10[exp_abs] : powers_of_10[exp_abs];
    }

    // Fallback to binary exponentiation for out-of-range exponents
    return pow(10, exp);
}

static void convert_to_zb_type(double value, zb_type_t type, void *result) {
    // Clip and convert the value based on the specified Zigbee type
    switch (type) {
        case ZB_INT24: {
            int32_t int24_value;

            if (value > 0x7FFFFF) {
                int24_value = 0x7FFFFF;
            } else if (value < -0x800000) {
                int24_value = -0x800000;
            } else {
                int24_value = (int32_t)value;
            }

            memcpy(result, &int24_value, 3);
            break;
        }
        case ZB_UINT16: {
            uint16_t uint16_value;

            if (value > UINT16_MAX) {
                uint16_value = UINT16_MAX;
            } else if (value < 0) {
                uint16_value = 0;
            } else {
                uint16_value = (uint16_t)value;
            }

            memcpy(result, &uint16_value, sizeof(uint16_t));
            break;
        }
        case ZB_INT16: {
            int16_t int16_value;

            if (value > INT16_MAX) {
                int16_value = INT16_MAX;
            } else if (value < INT16_MIN) {
                int16_value = INT16_MIN;
            } else {
                int16_value = (int16_t)value;
            }

            memcpy(result, &int16_value, sizeof(int16_t));
            break;
        }
        case ZB_UINT48: {
            uint64_t uint48_value;

            if (value > 0xFFFFFFFFFFFF) {
                uint48_value = 0xFFFFFFFFFFFF;
            } else if (value < 0) {
                uint48_value = 0;
            } else {
                uint48_value = (uint64_t)value;
            }

            memcpy(result, &uint48_value, 6);
            break;
        }
    }
}

void process_data(sml_list *entry, uint32_t data_type, uint32_t obis_flag, uint16_t zb_attr_id, uint16_t zb_cluster_id,
                  uint8_t zb_type, uint32_t multiplier) {
    if ((entry->value->type & SML_TYPE_FIELD) != data_type) {
        LOG_WRN("Unexpected Type.\n");
        return;
    }
    double value = sml_value_to_double(entry->value);
    int8_t scaler = (entry->scaler) ? *entry->scaler : 0;
    value = value * pow10(scaler) * multiplier;

    uint8_t zb_data[MAX_ZB_INT_BYTES] = {0};
    convert_to_zb_type(value, zb_type, &zb_data);

    ZB_ZCL_SET_ATTRIBUTE(SMZ_ENDPOINT_ID, zb_cluster_id, ZB_ZCL_CLUSTER_SERVER_ROLE, zb_attr_id, (zb_uint8_t *)&zb_data,
                         ZB_FALSE);
    atomic_or(&sml_obis_initialized, obis_flag);
}
/* Exported variables ---------------------------------------------------------*/
atomic_t sml_obis_initialized = 0;
/* Exported functions --------------------------------------------------------*/
void process_active_energy_import(sml_list *entry) {
    // Process and print imported active energy (OBIS 1.8.0). Unit: kWh
    process_data(entry, SML_TYPE_UNSIGNED, ACTIVE_ENERGY_IMPORT_FLAG,
                 ZB_ZCL_ATTR_METERING_CURRENT_SUMMATION_DELIVERED_ID, ZB_ZCL_CLUSTER_ID_METERING, ZB_UINT48, 1);
}

void process_current_active_power(sml_list *entry) {
    // Process and print current active power (OBIS 16.7.0). Unit: W
    process_data(entry, SML_TYPE_INTEGER, CURRENT_ACTIVE_POWER_FLAG, ZB_ZCL_ATTR_METERING_INSTANTANEOUS_DEMAND_ID,
                 ZB_ZCL_CLUSTER_ID_METERING, ZB_INT24, 1);
}

void process_voltage_l1(sml_list *entry) {
    // Process and print voltage value for phase L1 (OBIS 32.7.0). Unit: V
    process_data(entry, SML_TYPE_UNSIGNED, VOLTAGE_L1_FLAG, ZB_ZCL_ATTR_ELECTRICAL_MEASUREMENT_RMSVOLTAGE_ID,
                 ZB_ZCL_CLUSTER_ID_ELECTRICAL_MEASUREMENT, ZB_UINT16, 100);
}

void process_voltage_l2(sml_list *entry) {
    // Process and print voltage value for phase L2 (OBIS 52.7.0). Unit: V
    process_data(entry, SML_TYPE_UNSIGNED, VOLTAGE_L2_FLAG, ZB_ZCL_ATTR_ELECTRICAL_MEASUREMENT_RMSVOLTAGE_PHB_ID,
                 ZB_ZCL_CLUSTER_ID_ELECTRICAL_MEASUREMENT, ZB_UINT16, 100);
}

void process_voltage_l3(sml_list *entry) {
    // Process and print voltage value for phase L3 (OBIS 72.7.0). Unit: V
    process_data(entry, SML_TYPE_UNSIGNED, VOLTAGE_L3_FLAG, ZB_ZCL_ATTR_ELECTRICAL_MEASUREMENT_RMSVOLTAGE_PHC_ID,
                 ZB_ZCL_CLUSTER_ID_ELECTRICAL_MEASUREMENT, ZB_UINT16, 100);
}

void process_current_l1(sml_list *entry) {
    // Process and print current value for phase L1 (OBIS 31.7.0). Unit: A
    process_data(entry, SML_TYPE_UNSIGNED, CURRENT_L1_FLAG, ZB_ZCL_ATTR_ELECTRICAL_MEASUREMENT_RMSCURRENT_ID,
                 ZB_ZCL_CLUSTER_ID_ELECTRICAL_MEASUREMENT, ZB_UINT16, 100);
}

void process_current_l2(sml_list *entry) {
    // Process and print current value for phase L2 (OBIS 51.7.0). Unit: A
    process_data(entry, SML_TYPE_UNSIGNED, CURRENT_L2_FLAG, ZB_ZCL_ATTR_ELECTRICAL_MEASUREMENT_RMSCURRENT_PHB_ID,
                 ZB_ZCL_CLUSTER_ID_ELECTRICAL_MEASUREMENT, ZB_UINT16, 100);
}

void process_current_l3(sml_list *entry) {
    // Process and print current value for phase L3 (OBIS 71.7.0). Unit: A
    process_data(entry, SML_TYPE_UNSIGNED, CURRENT_L3_FLAG, ZB_ZCL_ATTR_ELECTRICAL_MEASUREMENT_RMSCURRENT_PHC_ID,
                 ZB_ZCL_CLUSTER_ID_ELECTRICAL_MEASUREMENT, ZB_UINT16, 100);
}

void process_frequency(sml_list *entry) {
    // Process and print the frequency value (OBIS 14.7.0). Unit Hz
    process_data(entry, SML_TYPE_UNSIGNED, FREQUENCY_FLAG, ZB_ZCL_ATTR_ELECTRICAL_MEASUREMENT_AC_FREQUENCY_ID,
                 ZB_ZCL_CLUSTER_ID_ELECTRICAL_MEASUREMENT, ZB_UINT16, 100);
}

void process_default_handler(sml_list *entry) {
    // Add your processing logic here if necessary
    LOG_INF("Default Handler: OBIS code %d-%d:%d.%d.%d*%d not found or not implemented.\n", entry->obj_name->str[0],
            entry->obj_name->str[1], entry->obj_name->str[2], entry->obj_name->str[3], entry->obj_name->str[4],
            entry->obj_name->str[5]);
}

void ignore_obis_value(sml_list *entry) {
    ARG_UNUSED(entry);
    // Do nothing and ignore the OBIS value
}
```
